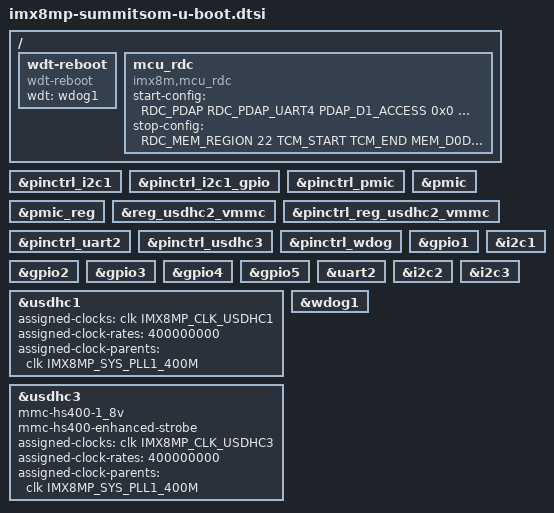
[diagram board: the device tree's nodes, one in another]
// SPDX-License-Identifier: GPL-2.0+
/*
 * Copyright 2021 Ezurio
 */

#include "imx8mp-sec-def.h"

#include "imx8mp-u-boot.dtsi"

/ {
	wdt-reboot {
		compatible = "wdt-reboot";
		wdt = <&wdog1>;
		bootph-pre-ram;
	};

	mcu_rdc {
		compatible = "imx8m,mcu_rdc";
			    /* rdc config when MCU starts
			     * peripheral:
			     *   UART4  --> Only Domian 1 can access
			     *   GPT1   --> Only Domian 1 can access
			     * memory:
			     *   TCM    --> Only Domian 1 can access (0x7E0000~0x81FFFF)
			     *   DDR    --> Only Domian 1 can access (0x47000000~0x48000000)
			     * end.
			     */
		start-config = <
			    RDC_PDAP RDC_PDAP_UART4 PDAP_D1_ACCESS 0x0 0x0
			    RDC_PDAP RDC_PDAP_GPT1  PDAP_D1_ACCESS 0x0 0x0
			    RDC_MEM_REGION 22 TCM_START TCM_END MEM_D1_ACCESS
			    RDC_MEM_REGION 39 0x3800000 0x4000000 MEM_D1_ACCESS
			    0x0      0x0            0x0  0x0 0x0
			  >;
			    /* rdc config when MCU stops
			     * memory:
			     *   TCM    --> domain 0/1 can access (0x7E0000~0x81FFFF)
			     *   DDR    --> domain 0/1 can access (0x47000000~0x48000000)
			     * end.
			     */
		stop-config = <
			    RDC_MEM_REGION 22 TCM_START TCM_END MEM_D0D1_ACCESS
			    RDC_MEM_REGION 39 0x3800000 0x4000000 MEM_D0D1_ACCESS
			    0x0      0x0            0x0  0x0 0x0
			  >;
	};
};

&pinctrl_i2c1 {
	bootph-all;
};

&pinctrl_i2c1_gpio {
	bootph-all;
};

&pinctrl_pmic {
	bootph-all;
};

&pmic {
	bootph-all;
};

&pmic_reg {
	bootph-all;
};

&reg_usdhc2_vmmc {
	bootph-pre-ram;
	//off-on-delay-us = <20000>;
};

&pinctrl_reg_usdhc2_vmmc {
	bootph-pre-ram;
};

&pinctrl_uart2 {
	bootph-pre-ram;
};

&pinctrl_usdhc3 {
	bootph-pre-ram;
};

&pinctrl_wdog {
	bootph-pre-ram;
};

&gpio1 {
	bootph-pre-ram;
};

&gpio2 {
	bootph-pre-ram;
};

&gpio3 {
	bootph-pre-ram;
};

&gpio4 {
	bootph-pre-ram;
};

&gpio5 {
	bootph-pre-ram;
};

&uart2 {
	bootph-pre-ram;
};

&i2c1 {
	bootph-all;
};

&i2c2 {
	bootph-pre-ram;
};

&i2c3 {
	bootph-pre-ram;
};

&usdhc1 {
	bootph-pre-ram;
	assigned-clocks = <&clk IMX8MP_CLK_USDHC1>;
	assigned-clock-rates = <400000000>;
	assigned-clock-parents = <&clk IMX8MP_SYS_PLL1_400M>;
};

&usdhc3 {
	bootph-pre-ram;
	mmc-hs400-1_8v;
	mmc-hs400-enhanced-strobe;
	assigned-clocks = <&clk IMX8MP_CLK_USDHC3>;
	assigned-clock-rates = <400000000>;
	assigned-clock-parents = <&clk IMX8MP_SYS_PLL1_400M>;
};

&wdog1 {
	bootph-pre-ram;
};
